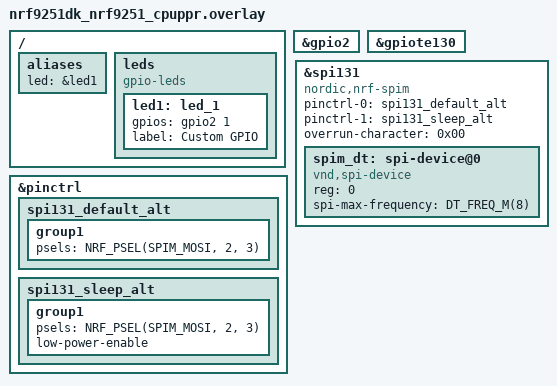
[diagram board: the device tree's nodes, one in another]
/*
 * Copyright (c) 2026 Nordic Semiconductor
 *
 * SPDX-License-Identifier: LicenseRef-Nordic-5-Clause
 */

/ {
	aliases {
		led = &led1;
	};

	leds {
		compatible = "gpio-leds";

		/* Move to other GPIO. */
		led1: led_1 {
			gpios = <&gpio2 1 GPIO_ACTIVE_HIGH>;
			label = "Custom GPIO";
		};
	};
};

&gpio2 {
	status = "okay";
};

&gpiote130 {
	status = "okay";
};

&pinctrl {
	spi131_default_alt: spi131_default_alt {
		group1 {
			psels = <NRF_PSEL(SPIM_MOSI, 2, 3)>;
		};
	};

	spi131_sleep_alt: spi131_sleep_alt {
		group1 {
			psels = <NRF_PSEL(SPIM_MOSI, 2, 3)>;
			low-power-enable;
		};
	};
};

&spi131 {
	compatible = "nordic,nrf-spim";
	status = "okay";
	pinctrl-0 = <&spi131_default_alt>;
	pinctrl-1 = <&spi131_sleep_alt>;
	pinctrl-names = "default", "sleep";
	overrun-character = <0x00>;

	spim_dt: spi-device@0 {
		compatible = "vnd,spi-device";
		reg = <0>;
		spi-max-frequency = <DT_FREQ_M(8)>;
	};
};
